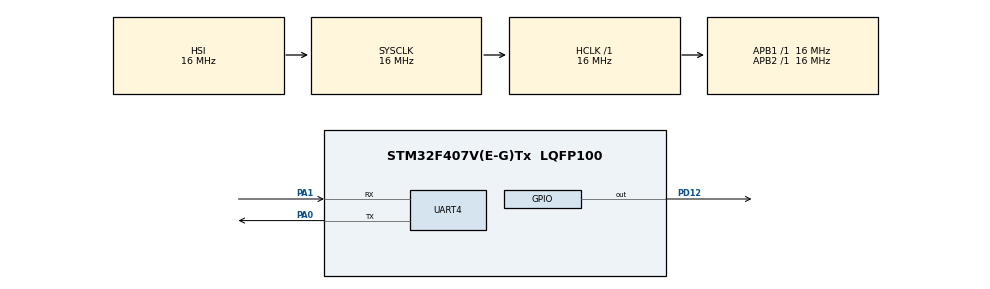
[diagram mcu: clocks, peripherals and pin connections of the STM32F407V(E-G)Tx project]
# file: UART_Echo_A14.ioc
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Mcu.Family=STM32F4
RCC.CortexFreq_Value=16000000
UART4.VirtualMode=Asynchronous
ProjectManager.StackSize=0x400
PA0-WKUP.Signal=UART4_TX
PA0-WKUP.Mode=Asynchronous
PA13.Signal=SYS_JTMS-SWDIO
ProjectManager.TargetToolchain=STM32CubeIDE
RCC.LSE_VALUE=32768
PA1.Signal=UART4_RX
RCC.AHBFreq_Value=16000000
RCC.HSE_VALUE=25000000
board=custom
RCC.VCOOutputFreq_Value=192000000
RCC.APB2Freq_Value=16000000
PA1.Mode=Asynchronous
PA14.Mode=Serial_Wire
PA13.Mode=Serial_Wire
Mcu.Name=STM32F407V(E-G)Tx
RCC.SYSCLKFreq_VALUE=16000000
Mcu.Package=LQFP100
PD12.Signal=GPIO_Output
PA14.Signal=SYS_JTCK-SWCLK
ProjectManager.HeapSize=0x200
RCC.HSI_VALUE=16000000
NVIC.PriorityGroup=NVIC_PRIORITYGROUP_4
RCC.APB1Freq_Value=16000000
NVIC.UART4_IRQn=true\:0\:0\:false\:false\:true\:true\:true

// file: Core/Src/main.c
/* USER CODE BEGIN Header */
/**
  ******************************************************************************
  * @file           : main.c
  * @brief          : Main program body
  ******************************************************************************
  * @attention
  *
  * <h2><center>&copy; Copyright (c) 2021 STMicroelectronics.
  * All rights reserved.</center></h2>
  *
  * This software component is licensed by ST under BSD 3-Clause license,
  * the "License"; You may not use this file except in compliance with the
  * License. You may obtain a copy of the License at:
  *                        opensource.org/licenses/BSD-3-Clause
  *
  ******************************************************************************
  */
/* USER CODE END Header */
#include "main.h"

UART_HandleTypeDef huart4;

/* USER CODE BEGIN PV */
char ar[30]="you send :";
char ar1[2]="\r\n";
char rx;
/* USER CODE END PV */

void SystemClock_Config(void);
static void MX_GPIO_Init(void);
static void MX_UART4_Init(void);

int main(void)
{

  /* MCU Configuration--------------------------------------------------------*/

  /* Reset of all peripherals, Initializes the Flash interface and the Systick. */
  HAL_Init();

  /* Configure the system clock */
  SystemClock_Config();

  /* Initialize all configured peripherals */
  MX_GPIO_Init();
  MX_UART4_Init();

  /* Infinite loop */
  while (1)
  {

    /* USER CODE BEGIN 3 */
	  HAL_UART_Receive_IT(&huart4, (uint8_t *)&rx, 1);
  }
  /* USER CODE END 3 */
}

void SystemClock_Config(void)
{
  RCC_OscInitTypeDef RCC_OscInitStruct = {0};
  RCC_ClkInitTypeDef RCC_ClkInitStruct = {0};

  /** Configure the main internal regulator output voltage
  */
  __HAL_RCC_PWR_CLK_ENABLE();
  __HAL_PWR_VOLTAGESCALING_CONFIG(PWR_REGULATOR_VOLTAGE_SCALE1);
  /** Initializes the RCC Oscillators according to the specified parameters
  * in the RCC_OscInitTypeDef structure.
  */
  RCC_OscInitStruct.OscillatorType = RCC_OSCILLATORTYPE_HSI;
  RCC_OscInitStruct.HSIState = RCC_HSI_ON;
  RCC_OscInitStruct.HSICalibrationValue = RCC_HSICALIBRATION_DEFAULT;
  RCC_OscInitStruct.PLL.PLLState = RCC_PLL_NONE;
  if (HAL_RCC_OscConfig(&RCC_OscInitStruct) != HAL_OK)
  {
    Error_Handler();
  }
  /** Initializes the CPU, AHB and APB buses clocks
  */
  RCC_ClkInitStruct.ClockType = RCC_CLOCKTYPE_HCLK|RCC_CLOCKTYPE_SYSCLK
                              |RCC_CLOCKTYPE_PCLK1|RCC_CLOCKTYPE_PCLK2;
  RCC_ClkInitStruct.SYSCLKSource = RCC_SYSCLKSOURCE_HSI;
  RCC_ClkInitStruct.AHBCLKDivider = RCC_SYSCLK_DIV1;
  RCC_ClkInitStruct.APB1CLKDivider = RCC_HCLK_DIV1;
  RCC_ClkInitStruct.APB2CLKDivider = RCC_HCLK_DIV1;

  if (HAL_RCC_ClockConfig(&RCC_ClkInitStruct, FLASH_LATENCY_0) != HAL_OK)
  {
    Error_Handler();
  }
}

static void MX_UART4_Init(void)
{

  huart4.Instance = UART4;
  huart4.Init.BaudRate = 115200;
  huart4.Init.WordLength = UART_WORDLENGTH_8B;
  huart4.Init.StopBits = UART_STOPBITS_1;
  huart4.Init.Parity = UART_PARITY_NONE;
  huart4.Init.Mode = UART_MODE_TX_RX;
  huart4.Init.HwFlowCtl = UART_HWCONTROL_NONE;
  huart4.Init.OverSampling = UART_OVERSAMPLING_16;
  if (HAL_UART_Init(&huart4) != HAL_OK)
  {
    Error_Handler();
  }

}

static void MX_GPIO_Init(void)
{
  GPIO_InitTypeDef GPIO_InitStruct = {0};

  /* GPIO Ports Clock Enable */
  __HAL_RCC_GPIOA_CLK_ENABLE();
  __HAL_RCC_GPIOD_CLK_ENABLE();

  /*Configure GPIO pin Output Level */
  HAL_GPIO_WritePin(GPIOD, GPIO_PIN_12, GPIO_PIN_RESET);

  /*Configure GPIO pin : PD12 */
  GPIO_InitStruct.Pin = GPIO_PIN_12;
  GPIO_InitStruct.Mode = GPIO_MODE_OUTPUT_PP;
  GPIO_InitStruct.Pull = GPIO_NOPULL;
  GPIO_InitStruct.Speed = GPIO_SPEED_FREQ_LOW;
  HAL_GPIO_Init(GPIOD, &GPIO_InitStruct);

}

/* USER CODE BEGIN 4 */
void HAL_UART_RxCpltCallback(UART_HandleTypeDef *huart)
{
  /* Prevent unused argument(s) compilation warning */
  //UNUSED(huart);
  /* NOTE: This function should not be modified, when the callback is needed,
           the HAL_UART_TxCpltCallback could be implemented in the user file
   */
	 HAL_GPIO_TogglePin(GPIOD, GPIO_PIN_12);
	 HAL_UART_Transmit(&huart4, (uint8_t *)&ar, 11, 10);
	 HAL_UART_Transmit(&huart4, (uint8_t *)&rx, 1, 10);
	 HAL_UART_Transmit(&huart4, (uint8_t *)&ar1, 3, 10);
}
/* USER CODE END 4 */

void Error_Handler(void)
{
  __disable_irq();
  while (1)
  {
  }
}

/************************ (C) COPYRIGHT STMicroelectronics *****END OF FILE****/
